VERSION ""

NS_ :

BS_:

BU_: ECU1 ECU2 ECU3

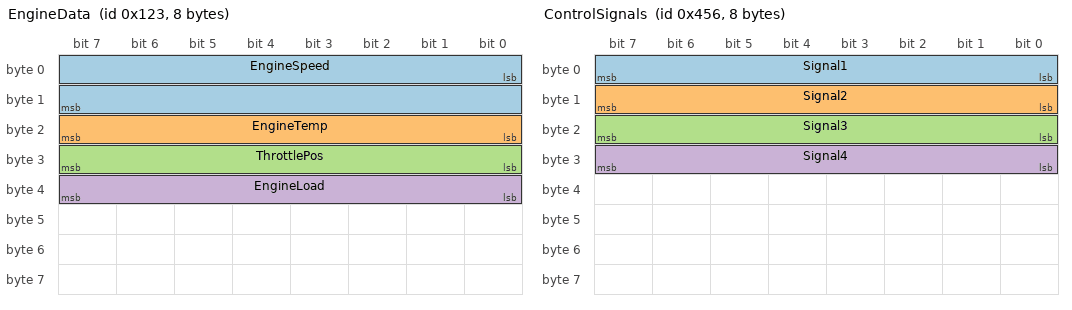
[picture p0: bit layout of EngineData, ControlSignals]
BO_ 291 EngineData: 8 ECU1
 SG_ EngineSpeed : 0|16@1+ (0.25,0) [0|16383.75] "rpm" ECU2,ECU3
 SG_ EngineTemp : 16|8@1+ (1,-40) [-40|215] "degC" ECU2,ECU3
 SG_ ThrottlePos : 24|8@1+ (0.4,0) [0|102] "%" ECU2,ECU3
 SG_ EngineLoad : 32|8@1+ (1,0) [0|255] "%" ECU2,ECU3

BO_ 512 VehicleSpeed: 2 ECU2
 SG_ Speed : 0|16@1+ (0.01,0) [0|655.35] "km/h" ECU1,ECU3

BO_ 768 GearInfo: 3 ECU2
 SG_ CurrentGear : 0|8@1+ (1,0) [0|10] "" ECU1,ECU3
 SG_ GearPosition : 8|8@1+ (1,0) [0|5] "" ECU1,ECU3

BO_ 1024 BatteryStatus: 1 ECU3
 SG_ BatteryVoltage : 0|8@1+ (0.1,0) [0|25.5] "V" ECU1,ECU2

BO_ 1110 ControlSignals: 8 ECU1
 SG_ Signal1 : 0|8@1+ (1,0) [0|255] "" ECU2,ECU3
 SG_ Signal2 : 8|8@1+ (1,0) [0|255] "" ECU2,ECU3
 SG_ Signal3 : 16|8@1+ (1,0) [0|255] "" ECU2,ECU3
 SG_ Signal4 : 24|8@1+ (1,0) [0|255] "" ECU2,ECU3

BO_ 1929 DiagnosticData: 4 ECU3
 SG_ ErrorCode : 0|16@1+ (1,0) [0|65535] "" ECU1,ECU2
 SG_ ErrorStatus : 16|8@1+ (1,0) [0|255] "" ECU1,ECU2

CM_ BO_ 291 "Engine data including speed, temperature, and throttle position";
CM_ SG_ 291 EngineSpeed "Engine rotation speed";
CM_ SG_ 291 EngineTemp "Engine coolant temperature";
CM_ BO_ 512 "Vehicle speed information";
CM_ BO_ 768 "Transmission gear information";

BA_DEF_ "BusType" STRING ;
BA_DEF_ BO_  "GenMsgCycleTime" INT 0 10000;
BA_DEF_DEF_  "BusType" "CAN";
BA_DEF_DEF_  "GenMsgCycleTime" 0;

BA_ "GenMsgCycleTime" BO_ 291 10;
BA_ "GenMsgCycleTime" BO_ 512 100;
BA_ "GenMsgCycleTime" BO_ 768 1000;

VAL_ 768 GearPosition 0 "Park" 1 "Reverse" 2 "Neutral" 3 "Drive" 4 "Sport" 5 "Manual" ;
